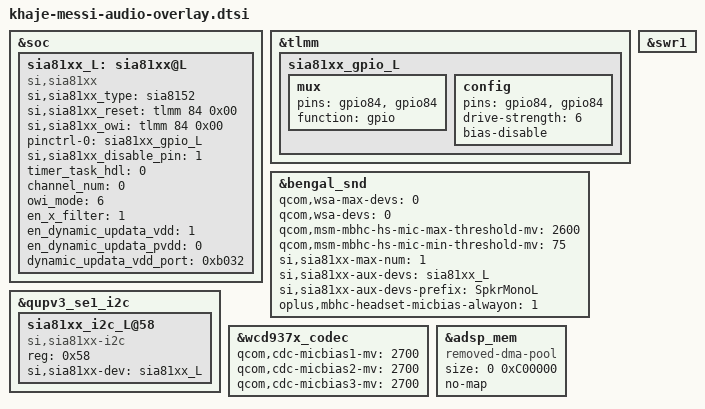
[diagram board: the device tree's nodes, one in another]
//bengal-qrd.dtsi
&soc {
	//#ifdef OPLUS_ARCH_EXTENDS
	sia81xx_L: sia81xx@L {
			compatible = "si,sia81xx";
			si,sia81xx_type = "sia8152";
			si,sia81xx_reset = <&tlmm 84 0x00>;
			si,sia81xx_owi = <&tlmm 84 0x00>;
			pinctrl-names = "sia81xx_gpio";
			pinctrl-0 = <&sia81xx_gpio_L>;

			si,sia81xx_disable_pin = <1>;

			/* the same value share a same task
			 * valid value range : 0 ~ 7 */
			timer_task_hdl = <0>;

			channel_num = <0>;
			owi_mode = <6>;
			en_x_filter = <1>;
			en_dynamic_updata_vdd = <1>;
			en_dynamic_updata_pvdd = <0>;
			dynamic_updata_vdd_port = <0xb032>;
	};
	//#endif /* OPLUS_ARCH_EXTENDS */
};

&tlmm {

	sia81xx_gpio_L: sia81xx_gpio_L {
		mux {
			pins = "gpio84", "gpio84";
			function = "gpio";
		};

		config {
			pins = "gpio84", "gpio84";
			drive-strength = <6>;
			bias-disable;
		};
	};
};

&bengal_snd {
	/delete-property/ qcom,wsa-max-devs;
	/delete-property/ qcom,wsa-devs;
	qcom,wsa-max-devs = <0>;
	qcom,wsa-devs = <0>;

	qcom,msm-mbhc-hs-mic-max-threshold-mv = <2600>;
	qcom,msm-mbhc-hs-mic-min-threshold-mv = <75>;

	si,sia81xx-max-num = <1>;
	si,sia81xx-aux-devs = <&sia81xx_L>;
	si,sia81xx-aux-devs-prefix = "SpkrMonoL";

	oplus,mbhc-headset-micbias-alwayon = <1>;
};

&qupv3_se1_i2c {

	sia81xx_i2c_L@58 {
		compatible = "si,sia81xx-i2c";
		reg = <0x58>;

		si,sia81xx-dev = <&sia81xx_L>;
	};

};

&swr1 {
	/delete-property/ qcom,disable-div2-clk-switch;
};
&wcd937x_codec {
	/delete-property/ qcom,cdc-micbias1-mv;
	/delete-property/ qcom,cdc-micbias2-mv;
	/delete-property/ qcom,cdc-micbias3-mv;
	qcom,cdc-micbias1-mv = <2700>;
	qcom,cdc-micbias2-mv = <2700>;
	qcom,cdc-micbias3-mv = <2700>;
};

&adsp_mem {
	compatible = "removed-dma-pool";
	size = <0 0xC00000>;
	no-map;
	/delete-property/ reusable;
};
